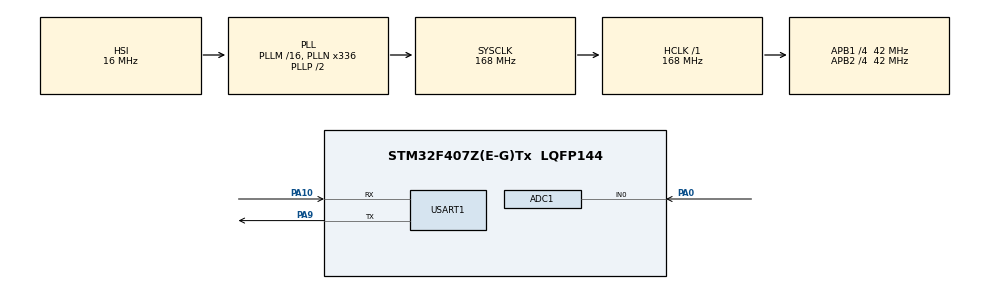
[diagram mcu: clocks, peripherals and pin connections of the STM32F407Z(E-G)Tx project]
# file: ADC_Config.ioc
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ADC1.Channel-1\#ChannelRegularConversion=ADC_CHANNEL_0
ADC1.Channel-5\#ChannelRegularConversion=ADC_CHANNEL_TEMPSENSOR
ADC1.ContinuousConvMode=ENABLE
ADC1.DMAContinuousRequests=ENABLE
ADC1.DiscontinuousConvMode=DISABLE
ADC1.EOCSelection=ADC_EOC_SEQ_CONV
ADC1.ExternalTrigConv=ADC_SOFTWARE_START
ADC1.NbrOfConversion=2
ADC1.NbrOfConversionFlag=1
ADC1.Rank-1\#ChannelRegularConversion=1
ADC1.Rank-5\#ChannelRegularConversion=2
ADC1.SamplingTime-1\#ChannelRegularConversion=ADC_SAMPLETIME_3CYCLES
ADC1.SamplingTime-5\#ChannelRegularConversion=ADC_SAMPLETIME_3CYCLES
ADC1.ScanConvMode=ENABLE
ADC1.master=1
Dma.ADC1.0.Direction=DMA_PERIPH_TO_MEMORY
Dma.ADC1.0.FIFOMode=DMA_FIFOMODE_DISABLE
Dma.ADC1.0.Instance=DMA2_Stream0
Dma.ADC1.0.MemDataAlignment=DMA_MDATAALIGN_HALFWORD
Dma.ADC1.0.MemInc=DMA_MINC_ENABLE
Dma.ADC1.0.Mode=DMA_NORMAL
Dma.ADC1.0.PeriphDataAlignment=DMA_PDATAALIGN_HALFWORD
Dma.ADC1.0.PeriphInc=DMA_PINC_DISABLE
Dma.ADC1.0.Priority=DMA_PRIORITY_LOW
Dma.Request0=ADC1
Mcu.Family=STM32F4
Mcu.Name=STM32F407Z(E-G)Tx
Mcu.Package=LQFP144
NVIC.ADC_IRQn=true\:0\:0\:false\:false\:true\:true\:true
NVIC.DMA2_Stream0_IRQn=true\:0\:0\:false\:false\:true\:false\:true
NVIC.PriorityGroup=NVIC_PRIORITYGROUP_4
NVIC.USART1_IRQn=true\:0\:0\:false\:false\:true\:true\:true
PA0-WKUP.Signal=ADCx_IN0
PA10.Mode=Asynchronous
PA10.Signal=USART1_RX
PA9.Mode=Asynchronous
PA9.Signal=USART1_TX
PC14-OSC32_IN.Mode=LSE-External-Clock-Source
PC14-OSC32_IN.Signal=RCC_OSC32_IN
PC15-OSC32_OUT.Mode=LSE-External-Clock-Source
PC15-OSC32_OUT.Signal=RCC_OSC32_OUT
PH0-OSC_IN.Mode=HSE-External-Clock-Source
PH0-OSC_IN.Signal=RCC_OSC_IN
PH1-OSC_OUT.Mode=HSE-External-Clock-Source
PH1-OSC_OUT.Signal=RCC_OSC_OUT
ProjectManager.HeapSize=0x200
ProjectManager.StackSize=0x400
ProjectManager.TargetToolchain=MDK-ARM V5
RCC.48MHZClocksFreq_Value=84000000
RCC.AHBFreq_Value=168000000
RCC.APB1CLKDivider=RCC_HCLK_DIV4
RCC.APB1Freq_Value=42000000
RCC.APB1TimFreq_Value=84000000
RCC.APB2CLKDivider=RCC_HCLK_DIV4
RCC.APB2Freq_Value=42000000
RCC.APB2TimFreq_Value=84000000
RCC.CortexFreq_Value=168000000
RCC.HCLKFreq_Value=168000000
RCC.HSE_VALUE=25000000
RCC.HSI_VALUE=16000000
RCC.LSE_VALUE=32768
RCC.PLLN=336
RCC.SYSCLKFreq_VALUE=168000000
RCC.SYSCLKSource=RCC_SYSCLKSOURCE_PLLCLK
RCC.VCOOutputFreq_Value=336000000
SH.ADCx_IN0.0=ADC1_IN0,IN0
USART1.VirtualMode=VM_ASYNC
VP_ADC1_TempSens_Input.Mode=IN-TempSens
board=custom

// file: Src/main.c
/* USER CODE BEGIN Header */
/**
  ******************************************************************************
  * @file           : main.c
  * @brief          : Main program body
  ******************************************************************************
  * @attention
  *
  * <h2><center>&copy; Copyright (c) 2019 STMicroelectronics.
  * All rights reserved.</center></h2>
  *
  * This software component is licensed by ST under BSD 3-Clause license,
  * the "License"; You may not use this file except in compliance with the
  * License. You may obtain a copy of the License at:
  *                        opensource.org/licenses/BSD-3-Clause
  *
  ******************************************************************************
  */
/* USER CODE END Header */

#include "main.h"
#include "adc.h"
#include "dma.h"
#include "usart.h"
#include "gpio.h"

/* USER CODE BEGIN Includes */
#include <stdarg.h>
#include <stdio.h>
/* USER CODE END Includes */

/* USER CODE BEGIN PV */
int VIS = 0;
/* USER CODE END PV */

void SystemClock_Config(void);
/* USER CODE BEGIN PFP */
void MyPrint(const char*frame,...)
{
  uint16_t Len;
	uint8_t s[100];
	va_list arg_ap;
	va_start(arg_ap, frame);
	Len = vsprintf((char*)s, frame, arg_ap);
	HAL_UART_Transmit(&huart1, s, Len, 1000);
}
/* USER CODE END PFP */

int main(void)
{
  /* USER CODE BEGIN 1 */
	uint16_t DMA_Buffer[30];
  /* USER CODE END 1 */

  /* MCU Configuration--------------------------------------------------------*/

  /* Reset of all peripherals, Initializes the Flash interface and the Systick. */
  HAL_Init();

  /* USER CODE BEGIN Init */
  uint8_t i=0;
  /* USER CODE END Init */

  /* Configure the system clock */
  SystemClock_Config();

  /* Initialize all configured peripherals */
  MX_GPIO_Init();
  MX_DMA_Init();
  MX_ADC1_Init();
  MX_USART1_UART_Init();
  /* USER CODE BEGIN 2 */
  HAL_ADC_Start_DMA(&hadc1, (uint32_t *)DMA_Buffer, 30);
  /* USER CODE END 2 */

  /* Infinite loop */
  /* USER CODE BEGIN WHILE */
  while (1)
  {
			if(VIS == 1){
				VIS = 0;
				for(int i=0;i<30;i++)
					MyPrint("ADC1 = %d\r\n",DMA_Buffer[i]);
			}

//		if(i>=2)
//		{
//			HAL_Delay(200);
//			HAL_ADC_Start(&hadc1);
//			i=0;
//		}

		//HAL_ADC_Start(&hadc1);

    /* USER CODE END WHILE */

  }
}

void SystemClock_Config(void)
{
  RCC_OscInitTypeDef RCC_OscInitStruct = {0};
  RCC_ClkInitTypeDef RCC_ClkInitStruct = {0};

  /** Configure the main internal regulator output voltage
  */
  __HAL_RCC_PWR_CLK_ENABLE();
  __HAL_PWR_VOLTAGESCALING_CONFIG(PWR_REGULATOR_VOLTAGE_SCALE1);
  /** Initializes the CPU, AHB and APB busses clocks
  */
  RCC_OscInitStruct.OscillatorType = RCC_OSCILLATORTYPE_HSI;
  RCC_OscInitStruct.HSIState = RCC_HSI_ON;
  RCC_OscInitStruct.HSICalibrationValue = RCC_HSICALIBRATION_DEFAULT;
  RCC_OscInitStruct.PLL.PLLState = RCC_PLL_ON;
  RCC_OscInitStruct.PLL.PLLSource = RCC_PLLSOURCE_HSI;
  RCC_OscInitStruct.PLL.PLLM = 16;
  RCC_OscInitStruct.PLL.PLLN = 336;
  RCC_OscInitStruct.PLL.PLLP = RCC_PLLP_DIV2;
  RCC_OscInitStruct.PLL.PLLQ = 4;
  if (HAL_RCC_OscConfig(&RCC_OscInitStruct) != HAL_OK)
  {
    Error_Handler();
  }
  /** Initializes the CPU, AHB and APB busses clocks
  */
  RCC_ClkInitStruct.ClockType = RCC_CLOCKTYPE_HCLK|RCC_CLOCKTYPE_SYSCLK
                              |RCC_CLOCKTYPE_PCLK1|RCC_CLOCKTYPE_PCLK2;
  RCC_ClkInitStruct.SYSCLKSource = RCC_SYSCLKSOURCE_PLLCLK;
  RCC_ClkInitStruct.AHBCLKDivider = RCC_SYSCLK_DIV1;
  RCC_ClkInitStruct.APB1CLKDivider = RCC_HCLK_DIV4;
  RCC_ClkInitStruct.APB2CLKDivider = RCC_HCLK_DIV4;

  if (HAL_RCC_ClockConfig(&RCC_ClkInitStruct, FLASH_LATENCY_5) != HAL_OK)
  {
    Error_Handler();
  }
}

/* USER CODE BEGIN 4 */
void HAL_ADC_ConvCpltCallback(ADC_HandleTypeDef* hadc)
{
  /* Prevent unused argument(s) compilation warning */
  UNUSED(hadc);
  /* NOTE : This function Should not be modified, when the callback is needed,
            the HAL_ADC_ConvCpltCallback could be implemented in the user file
   */
	VIS = 1;
}
/* USER CODE END 4 */

void Error_Handler(void)
{
}

/************************ (C) COPYRIGHT STMicroelectronics *****END OF FILE****/
